VERSION ""

NS_ :

BS_:

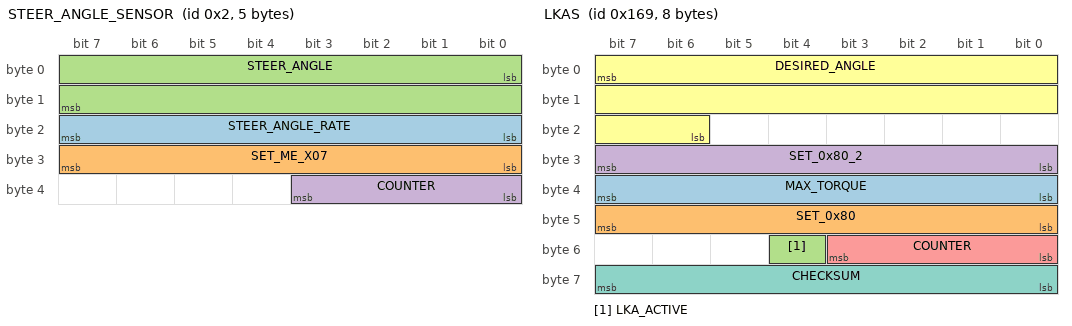
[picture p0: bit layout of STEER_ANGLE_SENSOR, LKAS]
BO_ 2 STEER_ANGLE_SENSOR: 5 XXX
 SG_ STEER_ANGLE_RATE : 16|8@1+ (1,0) [0|255] "" XXX
 SG_ SET_ME_X07 : 24|8@1+ (1,0) [0|255] "" XXX
 SG_ STEER_ANGLE : 0|16@1- (-0.1,0) [0|65535] "" XXX
 SG_ COUNTER : 32|4@1+ (1,0) [0|15] "" XXX

BO_ 361 LKAS: 8 XXX
 SG_ MAX_TORQUE : 39|8@0+ (0.01,0) [0|255] "Nm" XXX
 SG_ SET_0x80 : 47|8@0+ (1,0) [0|255] "" XXX
 SG_ LKA_ACTIVE : 52|1@0+ (1,0) [0|15] "" XXX
 SG_ SET_0x80_2 : 31|8@0+ (1,0) [0|255] "" XXX
 SG_ COUNTER : 51|4@0+ (1,0) [0|15] "" XXX
 SG_ DESIRED_ANGLE : 7|18@0+ (-0.01,1310) [-1311.43|1310] "" XXX
 SG_ CHECKSUM : 63|8@0+ (1,0) [0|255] "" XXX

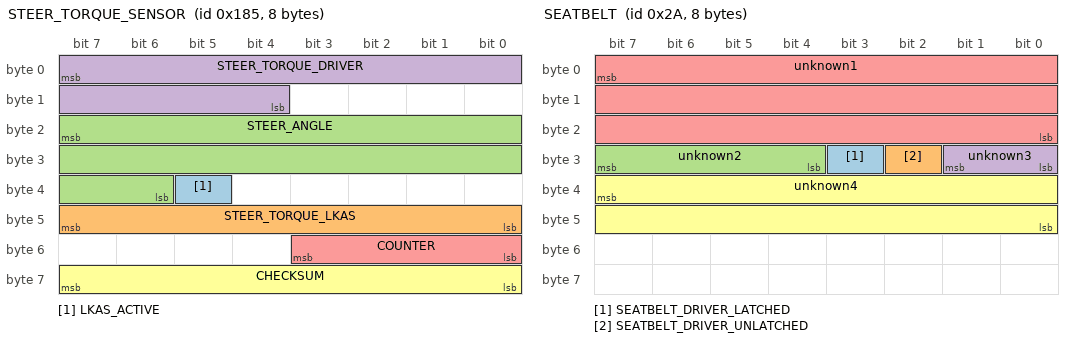
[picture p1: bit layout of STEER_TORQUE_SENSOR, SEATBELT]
BO_ 389 STEER_TORQUE_SENSOR: 8 XXX
 SG_ LKAS_ACTIVE : 37|1@0+ (1,0) [0|3] "" XXX
 SG_ STEER_TORQUE_LKAS : 47|8@0+ (1,0) [0|255] "" XXX
 SG_ STEER_ANGLE : 23|18@0+ (-0.01,1310) [0|262143] "" XXX
 SG_ STEER_TORQUE_DRIVER : 7|12@0+ (-0.01,20.47) [0|4095] "Nm" XXX
 SG_ COUNTER : 51|4@0+ (1,0) [0|15] "" XXX
 SG_ CHECKSUM : 63|8@0+ (1,0) [0|127] "" XXX

BO_ 645 WHEEL_SPEEDS_REAR: 8 XXX
 SG_ WHEEL_SPEED_RR : 7|16@0+ (0.005,0) [0|65535] "KPH" XXX
 SG_ WHEEL_SPEED_RL : 23|16@0+ (0.005,0) [0|65535] "KPH" XXX

BO_ 689 PROPILOT_HUD: 8 XXX
 SG_ LARGE_WARNING_FLASHING : 9|1@0+ (1,0) [0|1] "" XXX
 SG_ SIDE_RADAR_ERROR_FLASHING1 : 10|1@0+ (1,0) [0|1] "" XXX
 SG_ SIDE_RADAR_ERROR_FLASHING2 : 11|1@0+ (1,0) [0|1] "" XXX
 SG_ RIGHT_LANE_YELLOW_FLASH : 12|1@0+ (1,0) [0|1] "" XXX
 SG_ LEFT_LANE_YELLOW_FLASH : 13|1@0+ (1,0) [0|1] "" XXX
 SG_ LEAD_CAR : 14|1@0+ (1,0) [0|1] "" XXX
 SG_ LEAD_CAR_ERROR : 15|1@0+ (1,0) [0|1] "" XXX
 SG_ FRONT_RADAR_ERROR : 16|1@0+ (1,0) [0|1] "" XXX
 SG_ FRONT_RADAR_ERROR_FLASHING : 17|1@0+ (1,0) [0|1] "" XXX
 SG_ RIGHT_LANE_GREEN : 24|1@0+ (1,0) [0|1] "" XXX
 SG_ LEFT_LANE_GREEN : 25|1@0+ (1,0) [0|1] "" XXX
 SG_ SIDE_RADAR_ERROR_FLASHING3 : 27|1@0+ (1,0) [0|1] "" XXX
 SG_ LKAS_ERROR_FLASHING : 29|1@0+ (1,0) [0|1] "" XXX
 SG_ SAFETY_SHIELD_ACTIVE : 44|1@0+ (1,0) [0|1] "" XXX
 SG_ LARGE_STEERING_WHEEL_ICON : 61|2@0+ (1,0) [0|3] "" XXX
 SG_ RIGHT_LANE_GREEN_FLASH : 62|1@0+ (1,0) [0|1] "" XXX
 SG_ LEFT_LANE_GREEN_FLASH : 63|1@0+ (1,0) [0|1] "" XXX
 SG_ FOLLOW_DISTANCE : 3|2@0+ (1,0) [0|3] "" XXX
 SG_ AUDIBLE_TONE : 47|3@0+ (1,0) [0|8] "" XXX
 SG_ SPEED_SET_ICON : 7|2@0+ (1,0) [0|3] "" XXX
 SG_ SMALL_STEERING_WHEEL_ICON : 42|3@0+ (1,0) [0|7] "" XXX
 SG_ SET_SPEED : 39|8@0+ (1,0) [0|255] "" XXX
 SG_ unknown02 : 1|2@0+ (1,0) [0|3] "" XXX
 SG_ unknown05 : 5|2@0+ (1,0) [0|3] "" XXX
 SG_ unknown08 : 8|7@0+ (1,0) [0|63] "" XXX
 SG_ unknown26 : 26|1@0+ (1,0) [0|1] "" XXX
 SG_ unknown28 : 28|1@0+ (1,0) [0|1] "" XXX
 SG_ unknown31 : 31|2@0+ (1,0) [0|3] "" XXX
 SG_ unknown43 : 43|1@0+ (1,0) [0|1] "" XXX
 SG_ unknown55 : 55|8@0+ (1,0) [0|63] "" XXX
 SG_ unknown59 : 59|4@0+ (1,0) [0|15] "" XXX

BO_ 783 CRUISE_STATE: 3 XXX
 SG_ CRUISE_ENABLED : 3|1@0+ (1,0) [0|1] "" XXX

BO_ 1228 PROPILOT_HUD_INFO_MSG: 8 XXX
 SG_ NA_HIGH_ACCEL_TEMP : 0|1@0+ (1,0) [0|1] "" XXX
 SG_ SIDE_RADAR_NA_HIGH_CABIN_TEMP : 8|1@0+ (1,0) [0|1] "" XXX
 SG_ SIDE_RADAR_MALFUNCTION : 11|1@0+ (1,0) [0|1] "" XXX
 SG_ LKAS_MALFUNCTION : 12|1@0+ (1,0) [0|1] "" XXX
 SG_ FRONT_RADAR_MALFUNCTION : 13|1@0+ (1,0) [0|1] "" XXX
 SG_ SIDE_RADAR_NA_CLEAN_REAR_CAMERA : 14|1@0+ (1,0) [0|1] "" XXX
 SG_ NA_POOR_ROAD_CONDITIONS : 16|1@0+ (1,0) [0|1] "" XXX
 SG_ CURRENTLY_UNAVAILABLE : 17|1@0+ (1,0) [0|1] "" XXX
 SG_ SAFETY_SHIELD_OFF : 18|1@0+ (1,0) [0|1] "" XXX
 SG_ FRONT_COLLISION_NA_FRONT_RADAR_OBSTRUCTION : 20|1@0+ (1,0) [0|1] "" XXX
 SG_ PEDAL_MISSAPPLICATION_SYSTEM_ACTIVATED : 24|1@0+ (1,0) [0|1] "" XXX
 SG_ SIDE_IMPACT_NA_RADAR_OBSTRUCTION : 25|1@0+ (1,0) [0|1] "" XXX
 SG_ WARNING_DO_NOT_ENTER : 33|1@0+ (1,0) [0|1] "" XXX
 SG_ SIDE_IMPACT_SYSTEM_OFF : 34|1@0+ (1,0) [0|1] "" XXX
 SG_ SIDE_IMPACT_MALFUNCTION : 35|1@0+ (1,0) [0|1] "" XXX
 SG_ FRONT_COLLISION_MALFUNCTION : 36|1@0+ (1,0) [0|1] "" XXX
 SG_ SIDE_RADAR_MALFUNCTION2 : 37|1@0+ (1,0) [0|1] "" XXX
 SG_ LKAS_MALFUNCTION2 : 38|1@0+ (1,0) [0|1] "" XXX
 SG_ FRONT_RADAR_MALFUNCTION2 : 39|1@0+ (1,0) [0|1] "" XXX
 SG_ PROPILOT_NA_MSGS : 42|3@0+ (1,0) [0|7] "" XXX
 SG_ BOTTOM_MSG : 45|3@0+ (1,0) [0|7] "" XXX
 SG_ HANDS_ON_WHEEL_WARNING : 47|1@0+ (1,0) [0|1] "" XXX
 SG_ WARNING_STEP_ON_BRAKE_NOW : 51|1@0+ (1,0) [0|1] "" XXX
 SG_ PROPILOT_NA_FRONT_CAMERA_OBSTRUCTED : 52|1@0+ (1,0) [0|1] "" XXX
 SG_ PROPILOT_NA_HIGH_CABIN_TEMP : 53|1@0+ (1,0) [0|1] "" XXX
 SG_ WARNING_PROPILOT_MALFUNCTION : 54|1@0+ (1,0) [0|3] "" XXX
 SG_ ACC_UNAVAILABLE_HIGH_CABIN_TEMP : 62|1@0+ (1,0) [0|1] "" XXX
 SG_ ACC_NA_FRONT_CAMERA_IMPARED : 63|1@0+ (1,0) [0|1] "" XXX
 SG_ unknown07 : 7|7@0+ (1,0) [0|127] "" XXX
 SG_ unknown10 : 10|2@0+ (1,0) [0|3] "" XXX
 SG_ unknown15 : 15|1@0+ (1,0) [0|1] "" XXX
 SG_ unknown23 : 23|3@0+ (1,0) [0|7] "" XXX
 SG_ unknown19 : 19|1@0+ (1,0) [0|1] "" XXX
 SG_ unknown31 : 31|6@0+ (1,0) [0|63] "" XXX
 SG_ unknown32 : 32|1@0+ (1,0) [0|1] "" XXX
 SG_ unknown46 : 46|1@0+ (1,0) [0|1] "" XXX
 SG_ unknown50 : 50|3@0+ (1,0) [0|7] "" XXX
 SG_ unknown55 : 55|1@0+ (1,0) [0|1] "" XXX
 SG_ unknown61 : 61|6@0+ (1,0) [0|63] "" XXX

BO_ 1227 LKAS_SETTINGS: 8 XXX
 SG_ LKAS_ENABLED : 51|1@0+ (1,0) [0|1] "" XXX

BO_ 42 SEATBELT: 8 XXX
 SG_ SEATBELT_DRIVER_LATCHED : 27|1@1+ (1,0) [0|3] "" XXX
 SG_ SEATBELT_DRIVER_UNLATCHED : 26|1@0+ (1,0) [0|1] "" XXX
 SG_ unknown2 : 31|4@0+ (1,0) [0|15] "" XXX
 SG_ unknown3 : 24|2@1+ (1,0) [0|3] "" XXX
 SG_ unknown1 : 7|24@0+ (1,0) [0|16777215] "" XXX
 SG_ unknown4 : 39|16@0+ (1,0) [0|65535] "" XXX

BO_ 460 BRAKE_PEDAL: 8 XXX
 SG_ BRAKE_PEDAL : 7|8@0+ (1,0) [0|256] "" XXX

BO_ 569 CRUISE_THROTTLE: 8 XXX
 SG_ GAS_PEDAL_INVERTED : 15|8@0+ (1,0) [0|255] "" XXX
 SG_ GAS_PEDAL : 7|8@0+ (1,0) [0|255] "" XXX
 SG_ CRUISE_AVAILABLE : 17|1@0+ (1,0) [0|1] "" XXX
 SG_ unsure1 : 23|6@0+ (1,0) [0|63] "" XXX
 SG_ unsure2 : 16|1@0+ (1,0) [0|1] "" XXX
 SG_ unsure3 : 31|2@0+ (1,0) [0|3] "" XXX
 SG_ NO_BUTTON_PRESSED : 29|1@0+ (1,0) [0|1] "" XXX
 SG_ RES_BUTTON : 28|1@0+ (1,0) [0|1] "" XXX
 SG_ SET_BUTTON : 27|1@0+ (1,0) [0|1] "" XXX
 SG_ FOLLOW_DISTANCE_BUTTON : 26|1@0+ (1,0) [0|1] "" XXX
 SG_ CANCEL_BUTTON : 25|1@0+ (1,0) [0|1] "" XXX
 SG_ PROPILOT_BUTTON : 24|1@0+ (1,0) [0|1] "" XXX
 SG_ USER_BRAKE_PRESSED : 37|1@0+ (1,0) [0|1] "" XXX
 SG_ COUNTER : 32|2@1+ (1,0) [0|3] "" XXX
 SG_ unsure5 : 47|8@0+ (1,0) [0|255] "" XXX
 SG_ unsure6 : 55|8@0+ (1,0) [0|255] "" XXX
 SG_ unsure7 : 63|8@0+ (1,0) [0|255] "" XXX

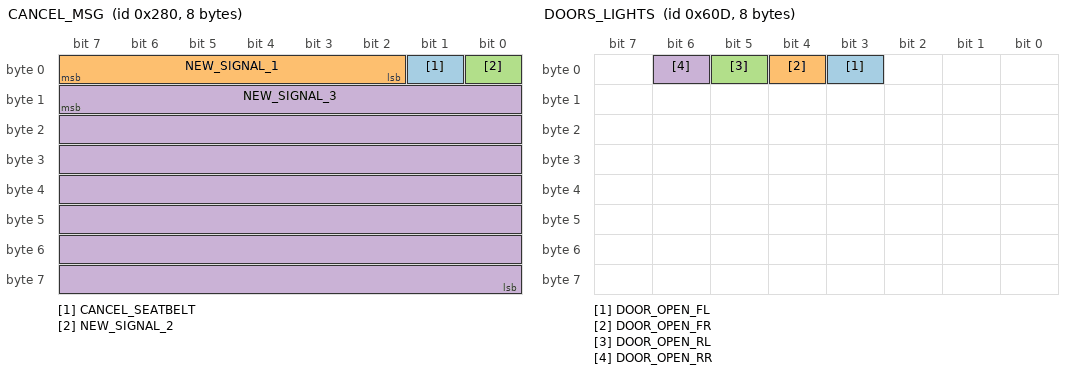
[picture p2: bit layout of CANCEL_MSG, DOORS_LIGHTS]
BO_ 640 CANCEL_MSG: 8 XXX
  SG_ CANCEL_SEATBELT : 1|1@0+ (1,0) [0|1] "" XXX
  SG_ NEW_SIGNAL_1 : 7|6@0+ (1,0) [0|63] "" XXX
  SG_ NEW_SIGNAL_2 : 0|1@0+ (1,0) [0|1] "" XXX
  SG_ NEW_SIGNAL_3 : 15|56@0+ (1,0) [0|72057594037927940] "" XXX

BO_ 644 WHEEL_SPEEDS_FRONT: 8 XXX
 SG_ WHEEL_SPEED_FR : 7|16@0+ (0.005,0) [0|65535] "KPH" XXX
 SG_ WHEEL_SPEED_FL : 23|16@0+ (0.005,0) [0|65535] "KPH" XXX

BO_ 852 ESP: 8 XXX
 SG_ ESP_DISABLED : 38|1@0+ (1,0) [0|1] "" XXX

BO_ 853 HUD_SETTINGS: 8 XXX
 SG_ SPEED_MPH : 37|1@0+ (1,0) [0|1] "" XXX

BO_ 856 LIGHTS: 8 XXX
 SG_ LEFT_BLINKER : 17|1@0+ (1,0) [0|1] "" XXX
 SG_ RIGHT_BLINKER : 18|1@0+ (1,0) [0|1] "" XXX

BO_ 1057 GEARBOX: 3 XXX
 SG_ GEAR_SHIFTER : 5|3@0+ (1,0) [0|255] "" XXX

BO_ 1549 DOORS_LIGHTS: 8 XXX
 SG_ DOOR_OPEN_FL : 3|1@0+ (1,0) [0|1] "" XXX
 SG_ DOOR_OPEN_FR : 4|1@0+ (1,0) [0|1] "" XXX
 SG_ DOOR_OPEN_RL : 5|1@0+ (1,0) [0|1] "" XXX
 SG_ DOOR_OPEN_RR : 6|1@0+ (1,0) [0|1] "" XXX

BU_: XXX

CM_ "AUTOGENERATED FILE, DO NOT EDIT";

CM_ "Imported file _comma.dbc starts here";
CM_ "Imported file _honda_common.dbc starts here";
CM_ SG_ 304 "Seems to be platform-agnostic";
CM_ SG_ 316 "Should exist on Nidec";
CM_ SG_ 420 BRAKE_HOLD_RELATED "On when Brake Hold engaged";
CM_ SG_ 490 LONG_ACCEL "wheel speed derivative, noisy and zero snapping";
CM_ SG_ 773 PASS_AIRBAG_ON "Might just be indicator light";
CM_ SG_ 773 PASS_AIRBAG_OFF "Might just be indicator light";
CM_ SG_ 780 CRUISE_SPEED "255 = no speed";
CM_ SG_ 780 PCM_SPEED "Used by Nidec";
CM_ SG_ 780 PCM_GAS "Used by Nidec";
CM_ SG_ 804 CRUISE_SPEED_PCM "255 = no speed";

CM_ "Imported file _bosch_2018.dbc starts here";
CM_ SG_ 450 EPB_STATE "3: On, 2: Disengaging, 1: Engaging, 0: Off";
CM_ SG_ 576 LINE_DISTANCE_VISIBLE "Length of line visible, undecoded";
CM_ SG_ 577 LINE_FAR_EDGE_POSITION "Appears to be a measure of line thickness, indicates location of the portion of the line furthest from the car, undecoded";
CM_ SG_ 577 LINE_PARAMETER "Unclear if this is low quality line curvature rate or if this is something else, but it is correlated with line curvature, undecoded";
CM_ SG_ 577 LINE_DASHED "1 = line is dashed";
CM_ SG_ 577 LINE_SOLID "1 = line is solid";

CM_ "Imported file _steering_sensors_a.dbc starts here";
CM_ "honda_civic_ex_2022_can.dbc starts here";

CM_ 446 "If exists, describes cruise faults and what the PCM uses for brake press detection.";
CM_ SG_ 456 IDLESTOP_ALLOW "allows car to turn off engine at a standstill";
CM_ SG_ 456 STANDSTILL "set to 1 when camera requests -4.0 m/s^2";

VAL_ 513 STATE 5 "FAULT_TIMEOUT" 4 "FAULT_STARTUP" 3 "FAULT_SCE" 2 "FAULT_SEND" 1 "FAULT_BAD_CHECKSUM" 0 "NO_FAULT" ;

VAL_ 497 SystemPowerMode 3 "Crank Request" 2 "Run" 1 "Accessory" 0 "Off";
VAL_ 497 SystemBackUpPowerMode 3 "Crank Request" 2 "Run" 1 "Accessory" 0 "Off";
VAL_ 481 DistanceButton 1 "Active" 0 "Inactive" ;
VAL_ 481 LKAButton 1 "Active" 0 "Inactive" ;
VAL_ 481 ACCButtons 6 "Cancel" 5 "Main" 3 "Set" 2 "Resume" 1 "None" ;
VAL_ 481 DriveModeButton 1 "Active" 0 "Inactive" ;
VAL_ 452 CruiseState 4 "Standstill" 3 "Faulted" 1 "Active" 0 "Off" ;
VAL_ 309 PRNDL 3 "R" 2 "D" 1 "N" 0 "P" ;
VAL_ 309 ESPButton 1 "Active" 0 "Inactive" ;
VAL_ 384 LKASteeringCmdActive 1 "Active" 0 "Inactive" ;
VAL_ 880 ACCCruiseState 2 "Adaptive" 3 "Adaptive" 4 "Non-adaptive" 5 "Non-adaptive" ;
VAL_ 880 ACCLeadCar 1 "Present" 0 "Not Present" ;
VAL_ 880 ACCGapLevel 3 "Far" 2 "Med" 1 "Near" 0 "Inactive" ;
VAL_ 880 ACCResumeButton 1 "Pressed" 0 "Depressed" ;
VAL_ 880 ACCCmdActive 1 "Active" 0 "Inactive" ;
VAL_ 388 HandsOffSWDetectionMode 2 "Failed" 1 "Enabled" 0 "Disabled" ;
VAL_ 388 HandsOffSWlDetectionStatus 1 "Hands On" 0 "Hands Off" ;
VAL_ 388 LKATorqueDeliveredStatus 3 "Failed" 2 "Temp. Limited" 1 "Active" 0 "Inactive" ;
VAL_ 489 BrakePedalPressed 1 "Pressed" 0 "Depressed" ;
VAL_ 715 GasRegenCmdActiveInv 1 "Inactive" 0 "Active" ;
VAL_ 715 GasRegenCmdActive 1 "Active" 0 "Inactive" ;
VAL_ 320 Intellibeam 1 "Active" 0 "Inactive" ;
VAL_ 320 HighBeamsActive 1 "Active" 0 "Inactive" ;
VAL_ 320 HighBeamsTemporary 1 "Active" 0 "Inactive" ;
VAL_ 501 PRNDL2 6 "L" 4 "D" 3 "N" 2 "R" 1 "P" 0 "Shifting";
VAL_ 501 TransmissionState 11 "Shifting" 10 "Reverse" 9 "Forward" 8 "Disengaged";
